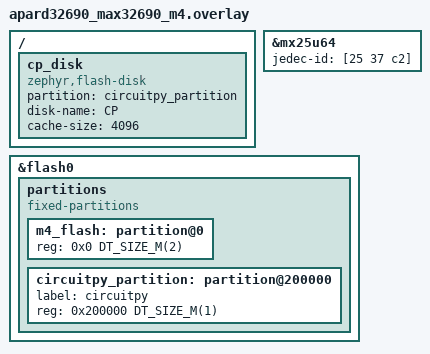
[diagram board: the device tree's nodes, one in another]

/ {
    /delete-node/ pmod-header;

    cp_disk {
        compatible = "zephyr,flash-disk";
        partition = <&circuitpy_partition>;
        disk-name = "CP";
        cache-size = <4096>;
    };
};

// TODO: Fix this in upstream! JEDEC ID appears backwards
&mx25u64 {
    jedec-id = [25 37 c2];
};

&flash0 {
    partitions {
        compatible = "fixed-partitions";
        #address-cells = <1>;
        #size-cells = <1>;

        m4_flash: partition@0 {
            reg = <0x0 DT_SIZE_M(2)>;
        };

        circuitpy_partition: partition@200000 {
            label = "circuitpy";
            reg = <0x200000 DT_SIZE_M(1)>;
        };
    };
};

#include "../app.overlay"
